# nrf9220_secure register map
Vendor: Nordic Semiconductor; Series: nRF92; File version: 1
CPU: CM33 r0p4, little endian, MPU, no FPU, 3 interrupt priority bits, 480 interrupts, 8 SAU regions
Registers are 32-bit, read-write, reset 0x0 unless marked. A register's access mark holds for its fields unless they carry their own. Offsets are from the block's base; [hi:lo] are bit positions; lines under a group give offsets from that group; {n}, {i} and the like mark numbered series; 'fields as' and 'values as' point back to an identical list.

## GLOBAL_FICR_NS — Factory Information Configuration Registers
Base 0x0FFFE000
0x00 SOCINFO group — Unspecified
  0x00 PARTNO ro reset 0xFFFFFFFF — Part number.
    [31:0] PART
  0x04 HWREVISION ro reset 0xFFFFFFFF — Hardware revision.
    [31:0] HWREVISION — Hardvare revision.
  0x08 PRODUCTIONREVISION ro reset 0xFFFFFFFF — Production reversion.
0x40 NFC group — Unspecified
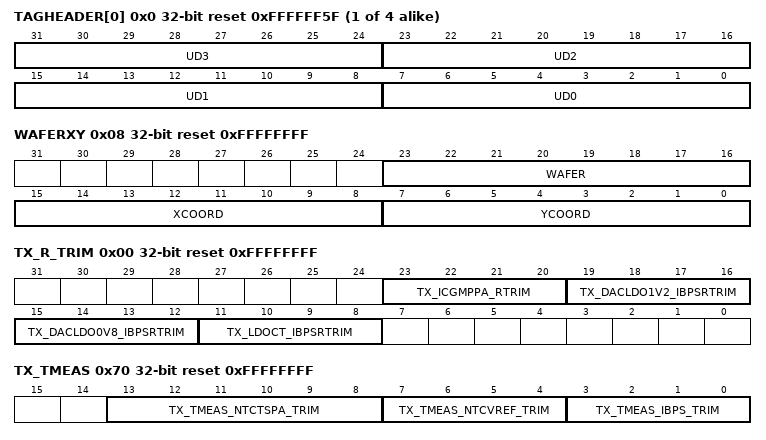
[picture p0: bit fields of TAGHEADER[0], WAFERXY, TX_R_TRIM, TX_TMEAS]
  {0x0+4j} TAGHEADER[{j}] (j=0..3) ro reset 0xFFFFFF5F — Description collection: Default header for NFC Tag.
    [8n+7:8n] UD{n} (n=0..3) — Unique identifier byte {n}
0x50 INFO group — Device info
  0x00 CONFIGID ro reset 0xFFFFFFFF — Configuration identifier
    [15:0] HWID — Identification number for the HW
  0x04 PART ro reset 0xFFFFFFFF — Part code
    [31:0] PART
      0xFFFFFFFF=Unspecified
  0x08 VARIANT ro reset 0xFFFFFFFF — Part Variant, Hardware version and Production configuration
    [31:0] VARIANT — Part Variant, Hardware version and Production configuration, encoded as ASCII
      0xFFFFFFFF=Unspecified
  0x0C PACKAGE ro reset 0xFFFFFFFF — Package option
    [31:0] PACKAGE
      0xFFFFFFFF=Unspecified
  0x10 RAM ro reset 0xFFFFFFFF — RAM variant
    [31:0] RAM
      0xFFFFFFFF=Unspecified
  0x14 MRAM ro reset 0xFFFFFFFF — MRAM variant
    [31:0] MRAM
      0xFFFFFFFF=Unspecified
  0x18 CODEPAGESIZE ro reset 0x1000 — Code memory page size in bytes
    [31:0] CODEPAGESIZE
      0xFFFFFFFF=Unspecified
  0x1C CODESIZE ro reset 0x100 — Code memory size
    [31:0] CODESIZE — Code memory size in number of pages
      0xFFFFFFFF=Unspecified
  0x20 DEVICETYPE ro
    [31:0] DEVICETYPE
      0=Die (Device is an physical DIE); 0xFFFFFFFF=FPGA (Device is an FPGA)
0xC0 PRODTEST group — Unspecified
  0x00 CP group — Unspecified
    {0x0+4k} LOTNR[{k}] (k=0..1) ro reset 0xFFFFFFFF — Description collection: Lot number.
      [31:0] LOTNR — Lot number
    0x08 WAFERXY ro reset 0xFFFFFFFF — Wafer number and die X,Y coordinate.
      [23:16] WAFER — Wafer number
      [15:8] XCOORD — Die x coordinate
      [7:0] YCOORD — Die y coordinate
    0x0C PROGVERSION1 ro reset 0xFFFFFFFF — CP1 test program version.
      [31:0] VAL — CP1 test program version
    0x10 PROGVERSION2 ro reset 0xFFFFFFFF — CP2 test program version.
      [31:0] VAL — CP2 test program version
    0x14 PASSID1 ro reset 0xFFFFFFFF — CP1 pass ID.
      [31:0] VAL
    0x18 PASSID2 ro reset 0xFFFFFFFF — CP2 pass ID.
      [31:0] VAL
    0x1C TIMESTAMP1 ro reset 0xFFFFFFFF — Timestamp for when CP1 starts or ends (YYYYMMDDTHHMMSS)
      [31:0] VAL — CP1 timestamp
    0x20 TIMESTAMP2 ro reset 0xFFFFFFFF — Timestamp for when CP2 starts or ends (YYYYMMDDTHHMMSS)
      [31:0] VAL — CP2 timestamp
  0x24 FT group — Unspecified
    0x00 PROGVERSION1 ro reset 0xFFFFFFFF — FT1 test program version.
      [31:0] PROGVERSION1 — FT1 test program version
    0x04 PROGVERSION2 ro reset 0xFFFFFFFF — FT2/EQA test program version.
      [31:0] PROGVERSION2 — FT2/EQA test program version
    0x08 PASSID1 ro reset 0xFFFFFFFF — FT1 pass ID.
      [31:0] VAL
    0x0C PASSID2 ro reset 0xFFFFFFFF — FT2/EQA pass ID.
      [31:0] VAL
    0x10 TIMESTAMP1 ro reset 0xFFFFFFFF — Timestamp for when FT1 starts or ends (YYYYMMDDTHHMMSS)
      [31:0] VAL — FT1 timestamp
    0x14 TIMESTAMP2 ro reset 0xFFFFFFFF — Timestamp for when FT2/EQA starts or ends (YYYYMMDDTHHMMSS)
      [31:0] VAL — FT2/EQA timestamp
0x100 TRIM group — Unspecified
  0x00 SYSCTRL group — Unspecified
    0x00 FLL16M group — Unspecified
      0x00 CONFIG group — Unspecified
        0x00 CFGCKSW16M ro reset 0xFFFFFFFF — Config value for SYSCTRL.FLL16M.CONFIG.CFGCKSW16M
          [31:0] VALUE — Config value
      0x04 TRIM group — Unspecified
        0x00 RCOARSE ro reset 0xFFFFFFFF — Trim value for SYSCTRL.FLL16M.TRIM.RCOARSE
          [31:0] VALUE — Trim value
        0x04 RFINE ro reset 0xFFFFFFFF — Trim value for SYSCTRL.FLL16M.TRIM.RFINE
          [31:0] VALUE — Trim value
        0x08 VSUP ro reset 0xFFFFFFFF — Trim value for SYSCTRL.FLL16M.TRIM.VSUP
          [31:0] VALUE — Trim value
        0x0C CKSW16MTRIM ro reset 0xFFFFFFFF — Trim value for SYSCTRL.FLL16M.TRIM.CKSW16MTRIM
          [31:0] VALUE — Trim value
        0x10 TCOEF ro reset 0xFFFFFFFF — Trim value for SYSCTRL.FLL16M.TRIM.TCOEF
          [31:0] VALUE — Trim value
    0x18 LFRC group — Unspecified
      0x00 CAL group — Unspecified
        0x00 LFRCOSCTRIM ro reset 0xFFFFFFFF — Trim value for SYSCTRL.LFRC.CAL.LFRCOSCTRIM
          [31:0] VALUE — Trim value
    0x1C LFXO group — Unspecified
      0x00 TRIM group — Unspecified
        0x00 PDLOWERTHR ro reset 0xFFFFFFFF — Trim value for SYSCTRL.LFXO.TRIM.PDLOWERTHR
          [31:0] VALUE — Trim value
        0x04 PDUPPERTHR ro reset 0xFFFFFFFF — Trim value for SYSCTRL.LFXO.TRIM.PDUPPERTHR
          [31:0] VALUE — Trim value
        0x08 BIAS ro reset 0xFFFFFFFF — Trim value for SYSCTRL.LFXO.TRIM.BIAS
          [31:0] VALUE — Trim value
        0x0C PIXO ro reset 0xFFFFFFFF — Trim value for SYSCTRL.LFXO.TRIM.PIXO
          [31:0] VALUE — Trim value
        0x10 TRIMBUS ro reset 0xFFFFFFFF — Trim value for SYSCTRL.LFXO.TRIM.TRIMBUS
          [31:0] VALUE — Trim value
    0x30 HFXO64M group — Unspecified
      0x00 TRIM group — Unspecified
        0x00 DOUBLERCOMP ro reset 0xFFFFFFFF — Trim value for SYSCTRL.HFXO64M.TRIM.DOUBLERCOMP
          [31:0] VALUE — Trim value
        0x04 CHIRPTUNE ro reset 0xFFFFFFFF — Trim value for SYSCTRL.HFXO64M.TRIM.CHIRPTUNE
          [31:0] VALUE — Trim value
        0x08 RTUNE ro reset 0xFFFFFFFF — Trim value for SYSCTRL.HFXO64M.TRIM.RTUNE
          [31:0] VALUE — Trim value
    0x3C LFLPRC group — Unspecified
      0x00 VSUP ro reset 0xFFFFFFFF — Trim value for SYSCTRL.LFLPRC.TRIM.VSUP
        [31:0] VALUE — Trim value
      0x04 RCOARSE ro reset 0xFFFFFFFF — Trim value for SYSCTRL.LFLPRC.TRIM.RCOARSE
        [31:0] VALUE — Trim value
      0x08 RFINE ro reset 0xFFFFFFFF — Trim value for SYSCTRL.LFLPRC.TRIM.RFINE
        [31:0] VALUE — Trim value
      0x0C PWMFINE ro reset 0xFFFFFFFF — Trim value for SYSCTRL.LFLPRC.TRIM.PWMFINE
        [31:0] VALUE — Trim value
    0x4C VDETPOF5V0 group — Unspecified
      0x00 TRIM group — Unspecified
        0x00 POFWARN ro reset 0xFFFFFFFF — Trim value for SYSCTRL.VDETPOF5V0.TRIM.POFWARN
          [31:0] VALUE — Trim value
    0x74 AUDIOPLL group — Unspecified
      0x00 TRIM group — Unspecified
        0x00 CTUNE ro reset 0xFFFFFFFF — Trim value for SYSCTRL.AUDIOPLL.TRIM.CTUNE
          [31:0] VALUE — Trim value
    0x78 AUDIOPLLPM group — Unspecified
      0x00 TRIM group — Unspecified
        0x00 VREFPM ro reset 0xFFFFFFFF — Trim value for SYSCTRL.AUDIOPLLPM.TRIM.VREFPM
          [31:0] VALUE — Trim value
    0x80 MBIAS group — Unspecified
      0x00 CONFIG group — Unspecified
        0x00 CFG ro reset 0xFFFFFFFF — Config value for SYSCTRL.MBIAS.CONFIG.CFG
          [31:0] VALUE — Trim value
      0x04 TRIM group — Unspecified
        0x00 MBIASIBPP ro reset 0xFFFFFFFF — Trim value for SYSCTRL.MBIAS.TRIM.MBIASIBPP
          [31:0] VALUE — Trim value
        0x04 MBIASIBPSR ro reset 0xFFFFFFFF — Trim value for SYSCTRL.MBIAS.TRIM.MBIASIBPSR
          [31:0] VALUE — Trim value
    0x8C OSCRFR group — Unspecified
      0x00 TRIM group — Unspecified
        0x00 OSC ro reset 0xFFFFFFFF — Trim value for SYSCTRL.OSCRFR.TRIM.OSC
          [31:0] VALUE — Trim value
        0x04 IBPSR ro reset 0xFFFFFFFF — Trim value for SYSCTRL.OSCRFR.TRIM.IBPSR
          [31:0] VALUE — Trim value
    0x94 HVBUCK1V1 group — Unspecified
      0x00 TRIM group — Unspecified
        0x00 BIASIBPP ro reset 0xFFFFFFFF — Trim value for SYSCTRL.HVBUCK1V1.TRIM.BIASIBPP
          [2:0] VALUE — Trim value
        0x04 BIASIBPSR ro reset 0xFFFFFFFF — Trim value for SYSCTRL.HVBUCK1V1.TRIM.BIASIBPSR
          [4:0] VALUE — Trim value
        0x08 VOUTHYST ro reset 0xFFFFFFFF — Trim value for SYSCTRL.HVBUCK1V1.TRIM.VOUTHYST
          [4:0] VALUE — Trim value
        0x0C VOUTOFFSET ro reset 0xFFFFFFFF — Trim value for SYSCTRL.HVBUCK1V8.TRIM.VOUTOFFSET
          [4:0] VALUE — Trim value
        0x10 ZCROSS ro reset 0xFFFFFFFF — Trim value for SYSCTRL.HVBUCK1V1.TRIM.ZCROSS
          [3:0] VALUE — Trim value
        0x14 HSILIM ro reset 0xFFFFFFFF — Trim value for SYSCTRL.HVBUCK1V1.TRIM.HSILIM
          [2:0] VALUE — Trim value
        0x18 VGND ro reset 0xFFFFFFFF — Trim value for SYSCTRL.HVBUCK1V1.TRIM.VGND
          [1:0] VALUE — Trim value
        0x1C COTTIMER ro reset 0xFFFFFFFF — Trim value for SYSCTRL.HVBUCK1V1.TRIM.COTTIMER
          [4:0] VALUE — Trim value
        0x20 FSMOSC ro reset 0xFFFFFFFF — Trim value for SYSCTRL.HVBUCK1V1.TRIM.FSMOSC
          [4:0] VALUE — Trim value
        0x24 DCOVOUT ro reset 0xFFFFFFFF — Trim value for SYSCTRL.HVBUCK1V1.TRIM.DCOVOUT
          [2:0] VALUE — Trim value
        0x28 DCOCOARSE ro reset 0xFFFFFFFF — Trim value for SYSCTRL.HVBUCK1V1.TRIM.DCOCOARSE
          [0] VALUE — Trim value
        0x2C DCOFINE ro reset 0xFFFFFFFF — Trim value for SYSCTRL.HVBUCK1V1.TRIM.DCOFINE
          [4:0] VALUE — Trim value
        0x30 VOUTPWM ro reset 0xFFFFFFFF — Trim value for SYSCTRL.HVBUCK1V1.TRIM.VOUTPWM
          [5:0] VALUE — Trim value
    0xC8 VREGAO0V8 group — Unspecified
      0x00 TRIM group — Unspecified
        0x00 IREF ro reset 0xFFFFFFFF — Trim value for SYSCTRL.VREGAO0V8.TRIM.IREF
          [31:0] VALUE — Trim value
        0x04 HIGHPOWER ro reset 0xFFFFFFFF — Trim value for SYSCTRL.VREGAO0V8.TRIM.HIGHPOWER
          [31:0] VALUE — Trim value
        0x08 LOWPOWER ro reset 0xFFFFFFFF — Trim value for SYSCTRL.VREGAO0V8.TRIM.LOWPOWER
          [31:0] VALUE — Trim value
        0x0C ULTRALOWPOWER ro reset 0xFFFFFFFF — Trim value for SYSCTRL.VREGAO0V8.TRIM.ULTRALOWPOWER
          [31:0] VALUE — Trim value
        0x10 BPDET ro reset 0xFFFFFFFF — Trim value for SYSCTRL.VREGAO0V8.TRIM.BPDET
          [31:0] VALUE — Trim value
    0xDC HVBUCK1V8 group — Unspecified
      0x00 TRIM group — Unspecified
        0x00 BIASIBPP ro reset 0xFFFFFFFF — Trim value for SYSCTRL.HVBUCK1V8.TRIM.BIASIBPP
          [2:0] VALUE — Trim value
        0x04 BIASIBPSR ro reset 0xFFFFFFFF — Trim value for SYSCTRL.HVBUCK1V8.TRIM.BIASIBPSR
          [4:0] VALUE — Trim value
        0x08 VOUTHYST ro reset 0xFFFFFFFF — Trim value for SYSCTRL.HVBUCK1V8.TRIM.VOUTHYST
          [4:0] VALUE — Trim value
        0x0C VOUTOFFSET ro reset 0xFFFFFFFF — Trim value for SYSCTRL.HVBUCK1V8.TRIM.VOUTOFFSET
          [4:0] VALUE — Trim value
        0x10 ZCROSS ro reset 0xFFFFFFFF — Trim value for SYSCTRL.HVBUCK1V8.TRIM.ZCROSS
          [3:0] VALUE — Trim value
        0x14 HSILIM ro reset 0xFFFFFFFF — Trim value for SYSCTRL.HVBUCK1V8.TRIM.HSILIM
          [2:0] VALUE — Trim value
        0x18 VGND ro reset 0xFFFFFFFF — Trim value for SYSCTRL.HVBUCK1V8.TRIM.VGND
          [1:0] VALUE — Trim value
        0x1C COTTIMER ro reset 0xFFFFFFFF — Trim value for SYSCTRL.HVBUCK1V8.TRIM.COTTIMER
          [4:0] VALUE — Trim value
        0x20 FSMOSC ro reset 0xFFFFFFFF — Trim value for SYSCTRL.HVBUCK1V8.TRIM.FSMOSC
          [4:0] VALUE — Trim value
        0x24 DCOVOUT ro reset 0xFFFFFFFF — Trim value for SYSCTRL.HVBUCK1V8.TRIM.DCOVOUT
          [2:0] VALUE — Trim value
        0x28 DCOCOARSE ro reset 0xFFFFFFFF — Trim value for SYSCTRL.HVBUCK1V8.TRIM.DCOCOARSE
          [0] VALUE — Trim value
        0x2C DCOFINE ro reset 0xFFFFFFFF — Trim value for SYSCTRL.HVBUCK1V8.TRIM.DCOFINE
          [4:0] VALUE — Trim value
        0x30 VOUTPWM ro reset 0xFFFFFFFF — Trim value for SYSCTRL.HVBUCK1V8.TRIM.VOUTPWM
          [5:0] VALUE — Trim value
    0x148 VREGMRAM130 group — Unspecified
      0x00 TRIM group — Unspecified
        0x00 VBG ro reset 0xFFFFFFFF — Trim value for SYSCTRL.VREGMRAM130.TRIM.VBG
          [31:0] VALUE — Trim value
        0x04 BIAS ro reset 0xFFFFFFFF — Trim value for SYSCTRL.VREGMRAM130.TRIM.BIAS
          [31:0] VALUE — Trim value
        0x08 VPR ro reset 0xFFFFFFFF — Trim value for SYSCTRL.VREGMRAM130.TRIM.VPR
          [31:0] VALUE — Trim value
        0x0C VREF ro reset 0xFFFFFFFF — Trim value for SYSCTRL.VREGMRAM130.TRIM.VREF
          [31:0] VALUE — Trim value
    0x158 VREGMRAM131 group — Unspecified
      0x00 TRIM group — Unspecified
        0x00 VBG ro reset 0xFFFFFFFF — Trim value for SYSCTRL.VREGMRAM131.TRIM.VBG
          [31:0] VALUE — Trim value
        0x04 BIAS ro reset 0xFFFFFFFF — Trim value for SYSCTRL.VREGMRAM131.TRIM.BIAS
          [31:0] VALUE — Trim value
        0x08 VPR ro reset 0xFFFFFFFF — Trim value for SYSCTRL.VREGMRAM131.TRIM.VPR
          [31:0] VALUE — Trim value
        0x0C VREF ro reset 0xFFFFFFFF — Trim value for SYSCTRL.VREGMRAM131.TRIM.VREF
          [31:0] VALUE — Trim value
    0x188 VDETAO0V8 group — Unspecified
      0x00 TRIM group — Unspecified
        0x00 BROWNOUT ro reset 0xFFFFFFFF — Trim value for SYSCTRL.VDETAO0V8.TRIM.BROWNOUT
          [31:0] VALUE — Trim value
        0x04 PWRGOOD ro reset 0xFFFFFFFF — Trim value for SYSCTRL.VDETAO0V8.TRIM.PWRGOOD
          [31:0] VALUE — Trim value
      0x08 CONFIG group — Unspecified
        0x00 BROWNOUTHP ro reset 0xFFFFFFFF — Config value for SYSCTRL.VDETAO0V8.CONFIG.BROWNOUTHP
          [31:0] VALUE — Config value
    0x194 VDETAO1V8 group — Unspecified
      0x00 TRIM group — Unspecified
        0x00 BROWNOUTLVLHIGH ro reset 0xFFFFFFFF — Trim value for SYSCTRL.VDETAO1V8.TRIM.BROWNOUTLVLHIGH
          [31:0] VALUE — Trim value
        0x04 BROWNOUTLVLLOW ro reset 0xFFFFFFFF — Trim value for SYSCTRL.VDETAO1V8.TRIM.BROWNOUTLVLLOW
          [31:0] VALUE — Trim value
    0x1A4 VDETAO5V0 group — Unspecified
      0x00 TRIM group — Unspecified
        0x00 PWRGOOD ro reset 0xFFFFFFFF — Trim value for SYSCTRL.VDETAO5V0.TRIM.PWRGOOD
          [31:0] VALUE — Trim value
    0x1A8 VDET1V0 group — Unspecified
      0x00 TRIM group — Unspecified
        0x00 PWRGOOD ro reset 0xFFFFFFFF — Trim value for SYSCTRL.VDET1V0.TRIM.PWRGOOD
          [31:0] VALUE — Trim value
    0x1AC HSFLL120 group — Unspecified
      0x00 TRIM group — Unspecified
        0x00 VSUP ro reset 0xFFFFFFFF — Trim value for SYSCTRL.HSFLL120.TRIM.VSUP
          [31:0] VALUE — Trim value
        {0x4+4m} COARSE[{m}] (m=0..5) ro reset 0xFFFFFFFF — Description collection: Trim value for SYSCTRL.HSFLL120.TRIM.COARSE
          [31:0] VALUE — Trim value
        {0x1C+4m} FINE[{m}] (m=0..5) ro reset 0xFFFFFFFF — Description collection: Trim value for SYSCTRL.HSFLL120.TRIM.FINE
          [31:0] VALUE — Trim value
        0x34 TCOEF ro reset 0xFFFFFFFF — Trim value for SYSCTRL.HSFLL120.TRIM.TCOEF
          [31:0] VALUE — Trim value
    0x254 MEMCONF120 group — Unspecified
      {0x0+4l} REPAIR[{l}] (l=0..3) group — Unspecified
        0x00 BITLINE ro reset 0xFFFFFFFF — Description cluster: Trim value for SYSCTRL.MEMCONF120.REPAIR[n].BITLINE
          [31:0] VALUE — Trim value
      {0x10+4l} RESERVED0[{l}] (l=0..14) group — Unspecified
        0x00 RESERVED0 ro reset 0xFFFFFFFF — Description cluster: Reserved for MEMCONF120 future use
          [31:0] VALUE — Trim value
      {0x4C+4l} BLOCKTYPE[{l}] (l=0..3) group — Unspecified
        0x00 TRIM ro reset 0xFFFFFFFF — Description cluster: Trim value for SYSCTRL.MEMCONF120.BLOCKTYPE[n].TRIM
          [31:0] VALUE — Trim value
      {0x5C+4l} RESERVED1[{l}] (l=0..2) group — Unspecified
        0x00 RESERVED1 ro reset 0xFFFFFFFF — Description cluster: Reserved for MEMCONF120 future use
          [31:0] VALUE — Trim value
    0x2BC MEMCONF130 group — Unspecified
      {0x0+4l} REPAIR[{l}] (l=0..0) group — Unspecified
        0x00 BITLINE ro reset 0xFFFFFFFF — Description cluster: Trim value for SYSCTRL.MEMCONF130.REPAIR[n].BITLINE
          [31:0] VALUE — Trim value
      {0x4+4l} BLOCKTYPE[{l}] (l=0..2) group — Unspecified
        0x00 TRIM ro reset 0xFFFFFFFF — Description cluster: Trim value for SYSCTRL.MEMCONF130.BLOCKTYPE[n].TRIM
          [31:0] VALUE — Trim value
  0x2CC GLOBAL group — Unspecified
    0x00 SAADC group — Unspecified
      {0x0+4l} CAL[{l}] (l=0..2) ro reset 0xFFFFFFFF — Description collection: Trim value for GLOBAL.SAADC.CAL
        [31:0] VALUE — Trim value
      0x0C CALREF ro reset 0xFFFFFFFF — Trim value for GLOBAL.SAADC.CALREF
        [31:0] VALUE — Trim value
      {0x10+4l} LINCALCOEFF[{l}] (l=0..5) ro reset 0xFFFFFFFF — Description collection: Trim value for GLOBAL.SAADC.TRIM.LINCALCOEFF
        [31:0] VALUE — Trim value
    0x28 TEMP group — Unspecified
      0x00 CALIB ro reset 0xFFFFFFFF — Trim value for GLOBAL.TEMP.CALIB
        [31:0] VALUE — Trim value
    0x2C NFCT group — Unspecified
      0x00 BIASCFG ro reset 0xFFFFFFFF — Trim value for NFCT.BIASCFG
        [31:0] VALUE — Trim value
  0x30C APPLICATION group — Unspecified
    0x00 HSFLL group — Unspecified
      0x00 TRIM group — Unspecified
        0x00 VSUP ro reset 0xFFFFFFFF — Trim value for APPLICATION.HSFLL.TRIM.VSUP
          [31:0] VALUE — Trim value
        {0x4+4m} COARSE[{m}] (m=0..5) ro reset 0xFFFFFFFF — Description collection: Trim value for APPLICATION.HSFLL.TRIM.COARSE
          [31:0] VALUE — Trim value
        {0x1C+4m} FINE[{m}] (m=0..5) ro reset 0xFFFFFFFF — Description collection: Trim value for APPLICATION.HSFLL.TRIM.FINE
          [31:0] VALUE — Trim value
        0x34 TCOEF ro reset 0xFFFFFFFF — Trim value for APPLICATION.HSFLL.TRIM.TCOEF
          [31:0] VALUE — Trim value
    0x38 MEMCONF group — Unspecified
      {0x0+4l} BLOCKTYPE[{l}] (l=0..3) group — Unspecified
        0x00 TRIM ro reset 0xFFFFFFFF — Description cluster: Trim value for APPLICATION.MEMCONF.BLOCKTYPE[n].TRIM
          [31:0] VALUE — Trim value
  0x3CC BOOT group — Unspecified
    0x00 GPIO group — Unspecified
      0x00 PORTCNF group — Unspecified
        0x00 DRIVECTRL group — Unspecified
          {0x0+4p} P[{p}] (p=0..1) ro reset 0xFFFFFFFF — Description collection: Trim value for GPIO.Pn.PORTCNF.DRIVECTRL
            [31:0] VALUE — Trim value
    0x10 HSFLL120 group — Unspecified
      0x00 TRIM group — Unspecified
        0x00 VSUP ro reset 0xFFFFFFFF — Trim value for SYSCTRL.HSFLL120.TRIM.VSUP
          [31:0] VALUE — Trim value
        0x04 COARSE ro reset 0xFFFFFFFF — Trim value for SYSCTRL.HSFLL120.TRIM.COARSE
          [31:0] VALUE — Trim value
        0x08 FINE ro reset 0xFFFFFFFF — Trim value for SYSCTRL.HSFLL120.TRIM.FINE
          [31:0] VALUE — Trim value
        0x0C TCOEF ro reset 0xFFFFFFFF — Trim value for SYSCTRL.HSFLL120.TRIM.TCOEF
          [31:0] VALUE — Trim value
    0x20 OTPC group — Unspecified
      0x00 WAITSTATES ro reset 0xFFFFFFFF — Config value for GLOBAL.OTPC.WAITSTATES
      0x04 FREQUENCY ro reset 0xFFFFFFFF — Config value for GLOBAL.OTPC.FREQUENCY
        [31:0] FREQUENCY — Frequency in MHz
  0x3F4 COMMON group — Unspecified
    0x00 FFFF ro reset 0xFFFFFFFF — Value to be written to multibit MIRROR register in MMIs (MIRROR=1)
      [31:0] FFFF — Mirror register value
    0x04 ZERO ro reset 0xFFFFFFFF — Value to be written to MIRROR register in MMIs (MIRROR=0)
      [31:0] ZERO — Mirror register value
    0x08 ONE ro reset 0xFFFFFFFF — Value to be written to MIRROR register in MMIs (MIRROR=1)
      [31:0] ONE — Mirror register value
  0x400 SECURE group — Unspecified
    0x00 HSFLL group — Unspecified
      0x00 TRIM group — Unspecified
        0x00 VSUP ro reset 0xFFFFFFFF — Trim value for SECURE.HSFLL.TRIM.VSUP
          [31:0] VALUE — Trim value
        {0x4+4m} COARSE[{m}] (m=0..5) ro reset 0xFFFFFFFF — Description collection: Trim value for SECURE.HSFLL.TRIM.COARSE
          [31:0] VALUE — Trim value
        {0x1C+4m} FINE[{m}] (m=0..5) ro reset 0xFFFFFFFF — Description collection: Trim value for SECURE.HSFLL.TRIM.FINE
          [31:0] VALUE — Trim value
    0x34 HSFLL200 group — Unspecified
      0x00 TRIM group — Unspecified
        0x00 VSUP ro reset 0xFFFFFFFF — Trim value for SECURE.HSFLL200.TRIM.VSUP
          [31:0] VALUE — Trim value
        {0x4+4m} COARSE[{m}] (m=0..3) ro reset 0xFFFFFFFF — Description collection: Trim value for SECURE.HSFLL200.TRIM.COARSE
          [31:0] VALUE — Trim value
        {0x14+4m} FINE[{m}] (m=0..3) ro reset 0xFFFFFFFF — Description collection: Trim value for SECURE.HSFLL200.TRIM.FINE
          [31:0] VALUE — Trim value
    0x58 MEMCONF group — Unspecified
      {0x0+4l} BLOCKTYPE[{l}] (l=0..7) group — Unspecified
        0x00 TRIM ro reset 0xFFFFFFFF — Description cluster: Trim value for SECURE.MEMCONF.BLOCKTYPE[n].TRIM
          [31:0] VALUE — Trim value
    0x78 MEMCONF200 group — Unspecified
      0x00 BLOCKTYPE group — Unspecified
        0x00 TRIM ro reset 0xFFFFFFFF — Trim value for SECURE.MEMCONF200.BLOCKTYPE.TRIM
          [31:0] VALUE — Trim value
    0x7C TCOEFS group — Unspecified
      0x00 TRIM group — Unspecified
        0x00 HSFLL ro reset 0xFFFFFFFF — Trim value for SECURE.HSFLL.TRIM.TCOEF
          [31:0] VALUE — Trim value
        0x04 HSFLL200 ro reset 0xFFFFFFFF — Trim value for SECURE.HSFLL200.TRIM.TCOEF
          [31:0] VALUE — Trim value
  0x500 CELLCORE group — Unspecified
    0x00 HSFLL group — Unspecified
      0x00 TRIM group — Unspecified
        0x00 VSUP ro reset 0xFFFFFFFF — Trim value for CELLCORE.HSFLL.TRIM.VSUP
          [31:0] VALUE — Trim value
        0x04 COARSE ro reset 0xFFFFFFFF — Trim value for CELLCORE.HSFLL.TRIM.COARSE
          [31:0] VALUE — Trim value
        0x08 FINE ro reset 0xFFFFFFFF — Trim value for CELLCORE.HSFLL.TRIM.FINE
          [31:0] VALUE — Trim value
        0x0C TCOEF ro reset 0xFFFFFFFF — Trim value for CELLCORE.HSFLL.TRIM.TCOEF
          [31:0] VALUE — Trim value
    0x10 MEMCONF group — Unspecified
      {0x0+4l} REPAIR[{l}] (l=0..0) group — Unspecified
        0x00 BITLINE ro reset 0xFFFFFFFF — Description cluster: Trim value for CELLCORE.MEMCONF.REPAIR[n].BITLINE
          [31:0] VALUE — Trim value
      {0x4+4l} BLOCKTYPE[{l}] (l=0..2) group — Unspecified
        0x00 TRIM ro reset 0xFFFFFFFF — Description cluster: Trim value for CELLCORE.MEMCONF.BLOCKTYPE[n].TRIM
          [31:0] VALUE — Trim value
    0x20 MCPLL group — Unspecified
      0x00 TRIM ro reset 0xFFFFFFFF — Trim value for CELLCORE.MCPLL.TRIM
        [3:0] LDO_RTUNE — Trim value
  0x524 CELLDSP group — Unspecified
    0x00 HSFLL group — Unspecified
      0x00 TRIM group — Unspecified
        0x00 VSUP ro reset 0xFFFFFFFF — Trim value for CELLDSP.HSFLL.TRIM.VSUP
          [31:0] VALUE — Trim value
        {0x4+4m} COARSE[{m}] (m=0..4) ro reset 0xFFFFFFFF — Description collection: Trim value for CELLDSP.HSFLL.TRIM.COARSE
          [31:0] VALUE — Trim value
        {0x18+4m} FINE[{m}] (m=0..4) ro reset 0xFFFFFFFF — Description collection: Trim value for CELLDSP.HSFLL.TRIM.FINE
          [31:0] VALUE — Trim value
        0x2C TCOEF ro reset 0xFFFFFFFF — Trim value for CELLDSP.HSFLL.TRIM.TCOEF
          [31:0] VALUE — Trim value
    0x30 MEMCONF group — Unspecified
      {0x0+4l} REPAIR[{l}] (l=0..1) group — Unspecified
        0x00 BITLINE ro reset 0xFFFFFFFF — Description cluster: Trim value for CELLDSP.MEMCONF.REPAIR[n].BITLINE
          [31:0] VALUE — Trim value
      {0x8+4l} RESERVED0[{l}] (l=0..9) group — Unspecified
        0x00 BITLINE ro reset 0xFFFFFFFF — Description cluster: Trim value for CELLDSP.MEMCONF.REPAIR[n].BITLINE
          [31:0] VALUE — Trim value
      {0x30+4l} BLOCKTYPE[{l}] (l=0..8) group — Unspecified
        0x00 TRIM ro reset 0xFFFFFFFF — Description cluster: Trim value for CELLDSP.MEMCONF.BLOCKTYPE[n].TRIM
          [31:0] VALUE — Trim value
  0x5A8 CELLRF group — Unspecified
    0x00 HSFLL group — Unspecified
      0x00 TRIM group — Unspecified
        0x00 VSUP ro reset 0xFFFFFFFF — Trim value for CELLRF.HSFLL.TRIM.VSUP
          [31:0] VALUE — Trim value
        0x04 COARSE ro reset 0xFFFFFFFF — Trim value for CELLRF.HSFLL.TRIM.COARSE
          [31:0] VALUE — Trim value
        0x08 FINE ro reset 0xFFFFFFFF — Trim value for CELLRF.HSFLL.TRIM.FINE
          [31:0] VALUE — Trim value
        0x0C TCOEF ro reset 0xFFFFFFFF — Trim value for CELLRF.HSFLL.TRIM.TCOEF
          [31:0] VALUE — Trim value
    0x10 MEMCONF group — Unspecified
      {0x0+4l} REPAIR[{l}] (l=0..0) group — Unspecified
        0x00 BITLINE ro reset 0xFFFFFFFF — Description cluster: Trim value for CELLRF.MEMCONF.REPAIR[n].BITLINE
          [31:0] VALUE — Trim value
      {0x4+4l} RESERVED0[{l}] (l=0..5) group — Unspecified
        0x00 BITLINE ro reset 0xFFFFFFFF — Description cluster: Trim value for CELLRF.MEMCONF.REPAIR[n].BITLINE
          [31:0] VALUE — Trim value
      {0x1C+4l} BLOCKTYPE[{l}] (l=0..2) group — Unspecified
        0x00 TRIM ro reset 0xFFFFFFFF — Description cluster: Trim value for CELLRF.MEMCONF.BLOCKTYPE[n].TRIM
          [31:0] VALUE — Trim value
    0x38 TXDFE group — Unspecified
      0x00 TX_R_TRIM ro reset 0xFFFFFFFF — Trim value for CELLRF.TXDFE.TX_R_TRIM
        [23:20] TX_ICGMPPA_RTRIM — Resistor tuning word
        [19:16] TX_DACLDO1V2_IBPSRTRIM — Resistor tuning word
        [15:12] TX_DACLDO0V8_IBPSRTRIM — Resistor tuning word (not used)
        [11:8] TX_LDOCT_IBPSRTRIM — Resistor tuning word
      0x04 TX_CALIB ro reset 0xFFFFFFFF — Trim value for CELLRF.TXDFE.TX_CALIB
        [3:0] TX_CALIB_CGMRTRIM — Trim value
      0x08 TX_IQ_COMP ro reset 0xFFFFFFFF — Trim value for CELLRF.TXDFE.TX_IQ_COMP
        [31:0] VALUE — Trim value
      0x0C TX_IQ_COMP_B13 ro reset 0xFFFFFFFF — Trim value for CELLRF.TXDFE.TX_IQ_COMP for BAND13
        [31:0] VALUE — Trim value
      {0x10+4l} TX_DC_COMP[{l}] (l=0..5) ro reset 0xFFFFFFFF — Description collection: Trim values for CELLRF.TXDFE.TX_DC_COMP (4db, 2DB, 0DB, N1DB, N3DB, N6DB)
        [31:0] VALUE — Trim value
      {0x28+4l} TX_DC_COMP_B13[{l}] (l=0..5) ro reset 0xFFFFFFFF — Description collection: Trim values for CELLRF.TXDFE.TX_DC_COMP_B13 for BAND13. (4db, 2DB, 0DB, N1DB, N3DB, N6DB)
        [31:0] VALUE — Trim value
      {0x40+4l} TX_ABB_DCCOMP[{l}] (l=0..5) ro reset 0xFFFFFFFF — Description collection: Trim values for CELLRF.TXDFE.TX_ABB_DCCOMP (4db, 2DB, 0DB, N1DB, N3DB, N6DB)
        [31:0] VALUE — Trim value
      {0x58+4l} TX_ABB_DCCOMP_B13[{l}] (l=0..5) ro reset 0xFFFFFFFF — Description collection: Trim values for CELLRF.TXDFE.TX_ABB_DCCOMP for BAND13. (4db, 2DB, 0DB, N1DB, N3DB, N6DB)
        [31:0] VALUE — Trim value
      0x70 TX_TMEAS ro reset 0xFFFFFFFF — Trim value for CELLRF.TXDFE.TX_TMEAS
        [13:8] TX_TMEAS_NTCTSPA_TRIM — Trim value
        [7:4] TX_TMEAS_NTCVREF_TRIM — Trim value
        [3:0] TX_TMEAS_IBPS_TRIM — Trim value
      0x74 TX_PPA_LDO_TRIM ro reset 0xFFFFFFFF — Trim value for CELLRF.TXDFE.TX_PPA_LDO_TRIM
        [2:0] VALUE — Trim value
      0x78 TX_PA_LDO_TRIM ro reset 0xFFFFFFFF — Trim value for CELLRF.TXDFE.TX_PA_LDO_TRIM
        [2:0] VALUE — Trim value
      0x7C TX_PA_BIAS_LDO_TRIM ro reset 0xFFFFFFFF — Trim value for CELLRF.TXDFE.TX_PA_BIAS_LDO_TRIM
        [2:0] VALUE — Trim value
      0x80 TX_LOBPF_C_TRIM_B11 ro reset 0xFFFFFFFF — Trim value for CELLRF.TXDFE.TX_LOBPF_C_TRIM for BAND11
        [31:0] TX_TXLO_BPF_CTUNE — Trim value for TXLO BPF resonance capacitance
      0x84 TX_LOBPF_C_TRIM_B2 ro reset 0xFFFFFFFF — Trim value for CELLRF.TXDFE.TX_LOBPF_C_TRIM for BAND2
        [31:0] TX_TXLO_BPF_CTUNE — Trim value TXLO BPF resonance capacitanc
      0x88 TX_LOBPF_C_TRIM_B41 ro reset 0xFFFFFFFF — Trim value for CELLRF.TXDFE.TX_LOBPF_C_TRIM for BAND41
        [31:0] TX_TXLO_BPF_CTUNE — Trim value TXLO BPF resonance capacitanc
    0xC4 RXDFE group — Unspecified
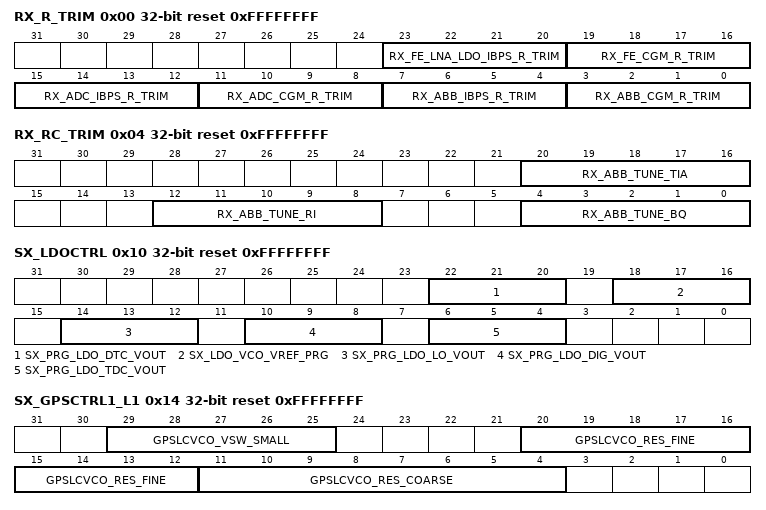
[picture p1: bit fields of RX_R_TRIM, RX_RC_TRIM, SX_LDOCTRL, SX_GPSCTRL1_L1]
      0x00 RX_R_TRIM ro reset 0xFFFFFFFF — Trim value for CELLRF.RXDFE.RX_R_TRIM
        [23:20] RX_FE_LNA_LDO_IBPS_R_TRIM — Resistor tuning word 2 s complement
        [19:16] RX_FE_CGM_R_TRIM — Resistor tuning word 2 s complement
        [15:12] RX_ADC_IBPS_R_TRIM — Resistor tuning word 2 s complement
        [11:8] RX_ADC_CGM_R_TRIM — Resistor tuning word 2 s complement
        [7:4] RX_ABB_IBPS_R_TRIM — Resistor tuning word 2 s complement
        [3:0] RX_ABB_CGM_R_TRIM — Resistor tuning word 2 s complement
      0x04 RX_RC_TRIM ro reset 0xFFFFFFFF — Trim value for CELLRF.RXDFE.RX_RC_TRIM
        [20:16] RX_ABB_TUNE_TIA — Resistor tuning word
        [12:8] RX_ABB_TUNE_RI — Resistor tuning word
        [4:0] RX_ABB_TUNE_BQ — Resistor tuning word
      {0x8+4l} TRIMSPARE[{l}] (l=0..3) ro reset 0xFFFFFFFF — Description collection: Trim value for CELLRF.RXDFE.TRIMSPARE
        [31:0] VALUE — Trim value
    0xDC SX group — Unspecified
      0x00 SX_R_TRIM reset 0xFFFFFFFF — Trim value for CELLRF.SX.SX_R_TRIM
        [3:0] SX_IBPS_R_TRIM — Trim code for the 10 uA current from KARHU_SX_BIAS
      {0x4+4l} TRIMSPARE[{l}] (l=0..2) ro reset 0xFFFFFFFF — Description collection: Trim value for CELLRF.SX.TRIMSPARE[n]
        [31:0] VALUE — Trim value
      0x10 SX_LDOCTRL ro reset 0xFFFFFFFF — Trim value for CELLRF.SX.SX_LDO_CTRL
        [22:20] SX_PRG_LDO_DTC_VOUT — Trim code for the REGDTC_0V8 supply domain LDO
        [18:16] SX_LDO_VCO_VREF_PRG — Trim code for the REGDCO_0V8 supply domain LDO
        [14:12] SX_PRG_LDO_LO_VOUT — Trim code for the LO_0V8 supply domain LDO
        [10:8] SX_PRG_LDO_DIG_VOUT — Trim code for the REGDIG_0V8 supply domain LDO
        [6:4] SX_PRG_LDO_TDC_VOUT — Trim code for the REGTDC_0V8 supply domain LDO
      0x14 SX_GPSCTRL1_L1 ro reset 0xFFFFFFFF — Trim value for CELLRF.SX.SX_GPSCTRL1 - L1 band
        [29:25] GPSLCVCO_VSW_SMALL — Trim value for GPSLCVCO small capacitance tuning bank control
        [20:12] GPSLCVCO_RES_FINE — Trim value for amplitude CTRL fine tuning
        [11:4] GPSLCVCO_RES_COARSE — Trim value for amplitude CTRL coarse tuning
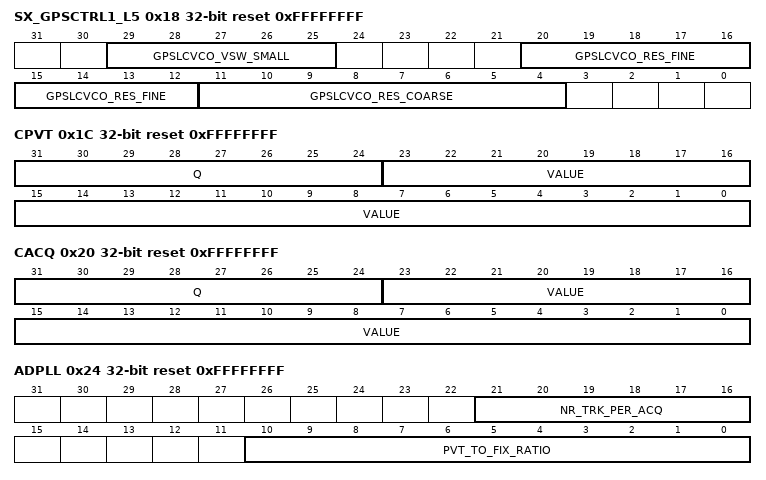
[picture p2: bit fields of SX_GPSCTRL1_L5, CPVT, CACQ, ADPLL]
      0x18 SX_GPSCTRL1_L5 ro reset 0xFFFFFFFF — Trim value for CELLRF.SX.SX_GPSCTRL1 - L5 band
        fields as TRIM.CELLRF.SX.SX_GPSCTRL1_L1
      0x1C CPVT ro reset 0xFFFFFFFF — Trim value for CELLRF.RFPLL.SX.CPVT
        [31:24] Q — Q Value
        [23:0] VALUE — PVT bank LSB capacitor size
      0x20 CACQ ro reset 0xFFFFFFFF — Trim value for CELLRF.RFPLL.SX.CACQ
        [31:24] Q — Q Value
        [23:0] VALUE — ACQ bank LSB capacitor size
      0x24 ADPLL ro reset 0xFFFFFFFF — Trim value for CELLRF.RFPLL.SX.ADPLL
        [21:16] NR_TRK_PER_ACQ — ACQ/TRK capacitor size ratio. Needed for knowing how many TRK steps to change when ACQ is changed by one step
        [10:0] PVT_TO_FIX_RATIO — The ratio between one step in the PVT capacitor bank vs the value when all capacitors are off.
    0x104 SENSORADC group — Unspecified
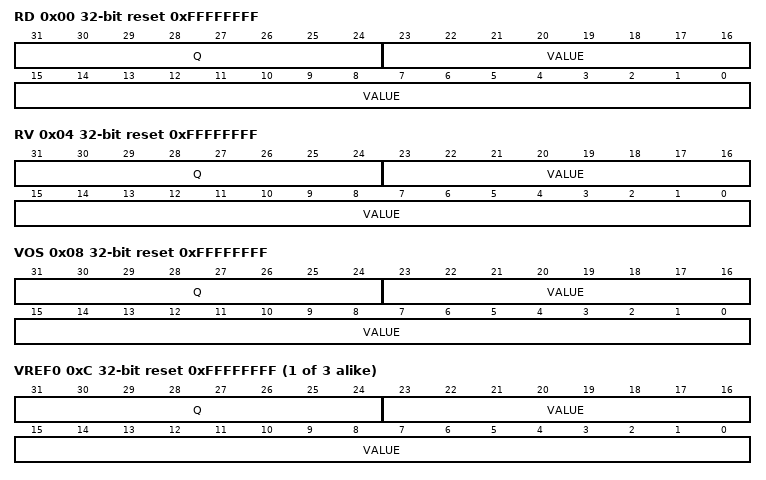
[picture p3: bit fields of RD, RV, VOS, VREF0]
      0x00 RD ro reset 0xFFFFFFFF — Trim value for CELLRF.SENSORADC.RD
        [31:24] Q — Q Value
        [23:0] VALUE — Value (Scaled with refclk (122.88 MHz))
      0x04 RV ro reset 0xFFFFFFFF — Trim value for CELLRF.SENSORADC.RV
        [31:24] Q — Q Value
        [23:0] VALUE — Value (refclk / RV (122.88 MHz / 8.0 MHz))
      0x08 VOS ro reset 0xFFFFFFFF — Trim value for CELLRF.SENSORADC.VOS
        [31:24] Q — Q Value
        [23:0] VALUE
      {0xC+4l} VREF{l} ro reset 0xFFFFFFFF (l=0..2) — Trim value for CELLRF.SENSORADC.VREF{l}
        [31:24] Q — Q Value
        [23:0] VALUE
      0x18 ICTRL ro reset 0xFFFFFFFF — Trim value for CELLRF.SENSORADC.ICTRL
        [31:0] VALUE — Trim value
      0x1C INTD25C ro reset 0xFFFFFFFF — Trim value for CELLRF.SENSORADC.INTD25C
        [31:0] VALUE — Trim value
      {0x20+4l} TRIMSPARE[{l}] (l=0..3) ro reset 0xFFFFFFFF — Description collection: Trim value for CELLRF.RFPLL.TRIMSPARE[n]
        [31:0] VALUE — Trim value
    0x134 COMMONTRIM group — Unspecified
      0x00 TX group — Unspecified
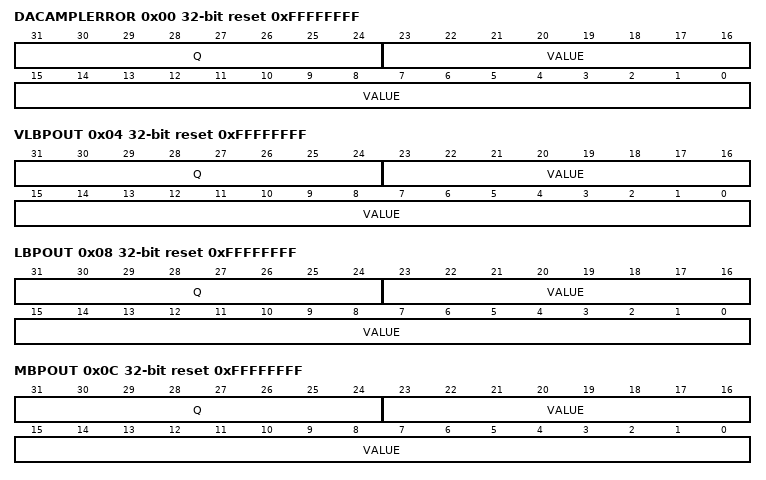
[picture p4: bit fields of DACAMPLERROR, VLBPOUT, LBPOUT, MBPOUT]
        0x00 DACAMPLERROR ro reset 0xFFFFFFFF — Trim value for CELLRF.COMMONTRIM.TX.DACAMPLERROR
          [31:24] Q — Q Value
          [23:0] VALUE
        0x04 VLBPOUT ro reset 0xFFFFFFFF — Trim value for CELLRF.COMMONTRIM.TX.VLBPOUT
          [31:24] Q — Q Value
          [23:0] VALUE
        0x08 LBPOUT ro reset 0xFFFFFFFF — Trim value for CELLRF.COMMONTRIM.TX.LBPOUT
          [31:24] Q — Q Value
          [23:0] VALUE
        0x0C MBPOUT ro reset 0xFFFFFFFF — Trim value for CELLRF.COMMONTRIM.TX.MBPOUT
          [31:24] Q — Q Value
          [23:0] VALUE
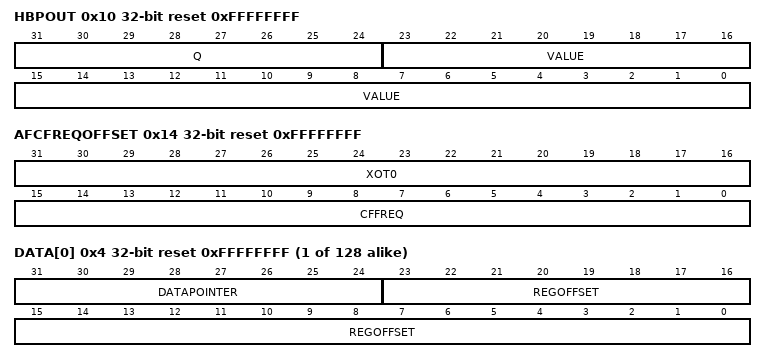
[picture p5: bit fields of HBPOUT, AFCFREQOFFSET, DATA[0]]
        0x10 HBPOUT ro reset 0xFFFFFFFF — Trim value for CELLRF.COMMONTRIM.TX.HBPOUT
          [31:24] Q — Q Value
          [23:0] VALUE
        0x14 AFCFREQOFFSET ro reset 0xFFFFFFFF — Trim value for CELLRF.COMMONTRIM.AFCFREQOFFSET.
          [31:16] XOT0 — Calibration temperature in Q8.
          [15:0] CFFREQ — Frequency offset in Q30 format.
0x800 SRAM group — Unspecified
  {0x0+4j} REPAIR[{j}] (j=0..63) ro reset 0xFFFFFFFF — Description collection: Raw RAM repair address and data pointer.
    [31:0] DATA — Raw RAM repair data
0x9A0 BOOT group — Unspecified
  0x00 SIZE ro reset 0xFFFFFFFF — Size of DATA group
    [31:0] VALUE — Number of trim values stored in DATA.
  {0x4+4j} DATA[{j}] (j=0..127) ro reset 0xFFFFFFFF — Description collection: Compressed address and data pointer.
    [31:24] DATAPOINTER — Pointer to location in TRIM group
    [23:0] REGOFFSET — Address offset to trim register
0xBFC CRC32 — CRC32 value for FICR (except this word)
  [31:0] VALUE — CRC32 value

## Notices in the file
Copyright (c) 2010 - 2025, Nordic Semiconductor ASA
All rights reserved.
Redistribution and use in source and binary forms, with or without modification,
are permitted provided that the following conditions are met:
1. Redistributions of source code must retain the above copyright notice, this
list of conditions and the following disclaimer.
2. Redistributions in binary form, except as embedded into a Nordic
Semiconductor ASA integrated circuit in a product or a software update for
such product, must reproduce the above copyright notice, this list of
conditions and the following disclaimer in the documentation and/or other
materials provided with the distribution.
3. Neither the name of Nordic Semiconductor ASA nor the names of its
contributors may be used to endorse or promote products derived from this
software without specific prior written permission.
4. This software, with or without modification, must only be used with a
Nordic Semiconductor ASA integrated circuit.
5. Any software provided in binary form under this license must not be reverse
engineered, decompiled, modified and/or disassembled.
THIS SOFTWARE IS PROVIDED BY NORDIC SEMICONDUCTOR ASA "AS IS" AND ANY EXPRESS
OR IMPLIED WARRANTIES, INCLUDING, BUT NOT LIMITED TO, THE IMPLIED WARRANTIES
OF MERCHANTABILITY, NONINFRINGEMENT, AND FITNESS FOR A PARTICULAR PURPOSE ARE
DISCLAIMED. IN NO EVENT SHALL NORDIC SEMICONDUCTOR ASA OR CONTRIBUTORS BE
LIABLE FOR ANY DIRECT, INDIRECT, INCIDENTAL, SPECIAL, EXEMPLARY, OR
CONSEQUENTIAL DAMAGES (INCLUDING, BUT NOT LIMITED TO, PROCUREMENT OF SUBSTITUTE
GOODS OR SERVICES; LOSS OF USE, DATA, OR PROFITS; OR BUSINESS INTERRUPTION)
HOWEVER CAUSED AND ON ANY THEORY OF LIABILITY, WHETHER IN CONTRACT, STRICT
LIABILITY, OR TORT (INCLUDING NEGLIGENCE OR OTHERWISE) ARISING IN ANY WAY OUT
OF THE USE OF THIS SOFTWARE, EVEN IF ADVISED OF THE POSSIBILITY OF SUCH DAMAGE.
